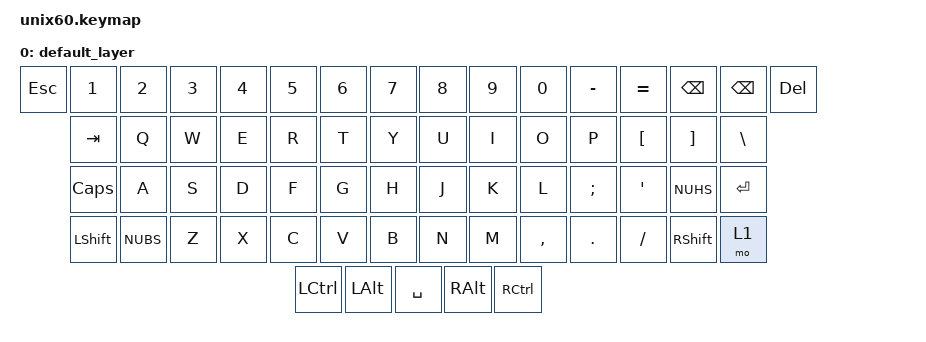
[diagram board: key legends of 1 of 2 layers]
/*
 * Copyright (c) 2020 The ZMK Contributors
 *
 * SPDX-License-Identifier: MIT
 */

#include <behaviors.dtsi>
#include <dt-bindings/zmk/keys.h>
#include <dt-bindings/zmk/bt.h>
#include <dt-bindings/zmk/rgb.h>

/ {
    keymap {
        compatible = "zmk,keymap";

        default_layer {
// ------------------------------------------------------------------------------------------------------------------
// | ESC |  1  |  2  |  3  |  4  |  5  |  6  |  7  |  8  |  9  |  0  |  -  |  =  | BSPC | DEL |
// | TAB  |  Q  |  W  |  E  |  R  |  T  |  Y  |  U  |  I  |  O  |  P  |  [  |  ]  |    \    |
// |  CAPS  |  A  |  S  |  D  |  F  |  G  |  H  |  J  |  K  |  L  |  ;  |  '  |     ENTER    |
// |   SHIFT  |  Z  |  X  |  C  |  V  |  B  |  N  |  M  |  ,  |  .  |  /  |  SHIFT   | MO(1) |
// |       CTRL |  ALT  |                 SPACE                   |  ALT  | CTRL |
// ------------------------------------------------------------------------------------------------------------------
            bindings = <
                &kp ESC         &kp N1 &kp N2 &kp N3 &kp N4 &kp N5 &kp N6 &kp N7 &kp   N8  &kp  N9 &kp  N0  &kp MINUS &kp EQUAL &kp BSPC &kp BSPC &kp DEL
                &kp TAB          &kp Q  &kp W  &kp E  &kp R  &kp T  &kp Y  &kp U  &kp   I   &kp  O  &kp   P  &kp LBKT &kp RBKT  &kp BSLH
                &kp CLCK          &kp A  &kp S  &kp D  &kp F  &kp G  &kp H  &kp J  &kp   K   &kp  L  &kp SEMI &kp SQT &kp NUHS  &kp RET
                &kp LSHFT &kp NUBS &kp Z  &kp X  &kp C  &kp V  &kp B  &kp N  &kp M  &kp COMMA &kp DOT &kp FSLH        &kp RSHFT &mo 1
                            &kp LCTRL &kp LALT                   &kp SPACE                 &kp  RALT  &kp  RCTRL
            >;
        };

        fn_layer {
            bindings = <
                &kp GRAVE       &kp F1       &kp F2       &kp F3       &kp F4       &kp F5       &kp F6     &kp F7     &kp F8     &kp F9     &kp F10    &kp F11    &kp F12    &bootloader    &trans
                &bt BT_CLR       &trans       &trans       &trans       &trans       &trans       &trans     &trans     &trans     &trans     &trans     &trans     &trans     &trans
                &trans            &bt BT_SEL 0 &bt BT_SEL 1 &bt BT_SEL 2 &bt BT_SEL 3 &bt BT_SEL 4 &kp LEFT   &kp DOWN   &kp UP     &kp RIGHT  &none      &none      &trans    &trans
                &trans    &none    &none        &none        &none        &none        &none        &none      &none      &none      &none      &trans     &trans        &trans
                        &trans   &trans                                              &trans                                                   &trans     &trans
            >;
        };
    };
};
